# MMCSD_MMC_48300000h register map
Vendor: Texas Instruments
Registers are 32-bit, access per field, reset values left out (the file's numbers can be read two ways) unless marked. A register's access mark holds for its fields unless they carry their own. Offsets are as the file gives them; [hi:lo] are bit positions.

## MMC (part 3 of 3)
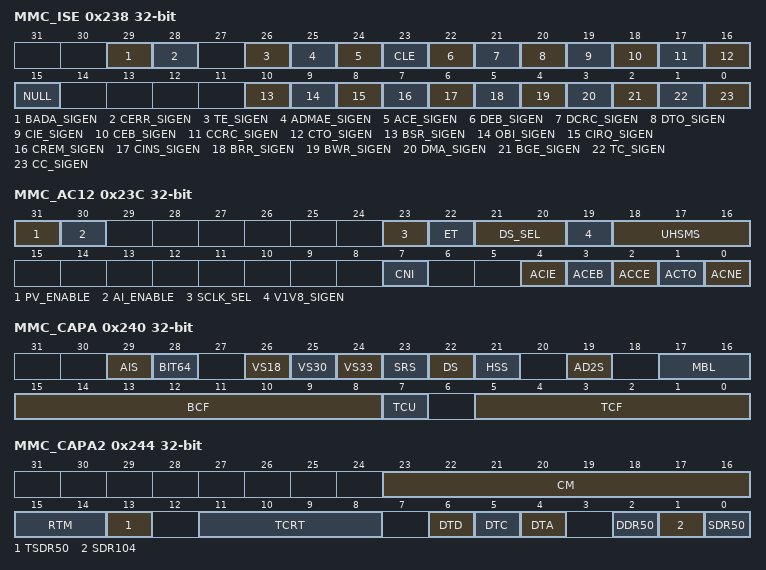
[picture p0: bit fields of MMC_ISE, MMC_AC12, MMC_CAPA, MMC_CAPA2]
0x238 MMC_ISE — Interrupt Signal Enable Register This register allows to enable/disable the module internal sources of status, on an event-by-event basis. MMCHS_ISE[31:16] = Error Interrupt Signal Enable MMCHS_ISE[15:0] = Normal Interrupt Signal Enable.
  [29] BADA_SIGEN rw — Bad access to data space Signal Enable 0 Masked1 Enabled
  [28] CERR_SIGEN rw — Card Error Interrupt Signal Enable 0 Masked1 Enabled
  [26] TE_SIGEN rw — Tuning Error Signal Enable 0 Masked1 Enabled
  [25] ADMAE_SIGEN rw — ADMA Error Signal Enable 0 Masked1 Enabled
  [24] ACE_SIGEN rw — Auto CMD Error Signal Enable 0 Masked1 Enabled
  [23] CLE ro — Reserved bit.Current limit error is not supported.These bits are initialized to zero, and writes to them are ignored.
  [22] DEB_SIGEN rw — Data End Bit Error Signal Enable 0 Masked1 Enabled
  [21] DCRC_SIGEN rw — Data CRC Error Signal Enable 0 Masked1 Enabled
  [20] DTO_SIGEN rw — Data Timeout Error Signal Enable 0 Masked1 Enabled
  [19] CIE_SIGEN rw — Command Index Error Signal Enable 0 Masked1 Enabled
  [18] CEB_SIGEN rw — Command End Bit Error Signal Enable 0 Masked1 Enabled
  [17] CCRC_SIGEN rw — Command CRC Error Signal Enable 0 Masked1 Enabled
  [16] CTO_SIGEN rw — Command timeout Error Signal Enable 0 Masked1 Enabled
  [15] NULL ro — Fixed to 0The host driver shall control error interrupts using the Error Interrupt Signal Enable register.Writes to this bit are ignored
  [10] BSR_SIGEN rw — Boot Status Signal Enable A write to this register when MMCSD_CON[BOOT_ACK] is set to 0x0 is ignored. 0 Masked1 Enabled
  [9] OBI_SIGEN rw — Out-Of-Band Interrupt Signal Enable A write to this register when MMCSD_CON[OBIE] is set to '0' is ignored. 0 Masked1 Enabled
  [8] CIRQ_SIGEN rw — Card Interrupt Signal Enable 0 Masked1 Enabled
  [7] CREM_SIGEN rw — Card Removal Signal Enable 0 Masked1 Enabled
  [6] CINS_SIGEN rw — Card Insertion Signal Enable 0 Masked1 Enabled
  [5] BRR_SIGEN rw — Buffer Read Ready Signal Enable 0 Masked1 Enabled
  [4] BWR_SIGEN rw — Buffer Write Ready Signal Enable 0 Masked1 Enabled
  [3] DMA_SIGEN rw — DMA Interrupt Signal Enable 0 Masked1 Enabled
  [2] BGE_SIGEN rw — Black Gap Event Signal Enable 0 Masked1 Enabled
  [1] TC_SIGEN rw — Transfer Completed Status Enable 0 Masked1 Enabled
  [0] CC_SIGEN rw — Command Complete Status Enable 0 Masked1 Enabled
0x23C MMC_AC12 — Host Control 2 Register and Auto CMD Error Status Register This register is used to indicate CMD12 response error of Auto CMD12 and CMD23 response error of Auto CMD23. The Host driver can determine what kind of Auto CMD12 / CMD23 errors occur by this register. Auto CMD23 errors are indicated in bit 04-01.This register is valid only when the Auto CMD Error is set.
  [31] PV_ENABLE rw — Preset Value Enable Host Controller Version 3.00 supports this bit. As the operating SDCLK frequency and I/O driver strength depend on the Host System implementation, it is difficult to determine these parameters in the Standard Host Driver. When Preset Value Enable is set, automatic SDCLK frequency generation and driver strength selection is performed without considering system specific conditions. This bit enables the functions defined in the Preset Value registers. If this bit is set to 0, SDCLK Frequency Select, Clock Generator Select in the Clock Control register and Driver Strength Select in Host Control 2 register are set by Host Driver. If this bit is set to 1, SDCLK Frequency Select, Clock Generator Select in the Clock Control register and Driver Strength Select in Host Control 2 register are set by Host Controller as specified in the Preset Value registers. 0 SDCLK and Driver Strength are controlled by Host Driver.1 Automatic Selection by Preset Value are Enabled.
  [30] AI_ENABLE rw — Asynchronous Interrupt Enable This bit can be set to 1 if a card supports asynchronous interrupts and Asynchronous Interrupt Support is set to 1 in the Capabilities register. Asynchronous interrupt is effective when DAT[1] interrupt is used in 4-bit SD mode [and zero is set to Interrupt Pin Select in the Shared Bus Control register]. If this bit is set to 1, the Host Driver can stop the SDCLK during asynchronous interrupt period to save power. During this period, the Host Controller continues to deliver the Card Interrupt to the host when it is asserted by the Card. 0 Disabled1 Enabled
  [23] SCLK_SEL rw — Sampling Clock Select Host Controller uses this bit to select sampling clock to receive CMD and DAT. This bit is set by tuning procedure and valid after the completion of tuning [when Execute Tuning is cleared]. Setting 1 means that tuning is completed successfully and setting 0 means that tuning is failed. Writing 1 to this bit is meaningless and ignored. A tuning circuit is reset by Writing to 0. This bit can be cleared with setting Execute Tuning. Once the tuning circuit is reset, it will take time to complete tuning sequence. Therefore, Host Driver should keep this bit to 1 to perform re-tuning sequence to compete re-tuning sequence in a short time. Change of this bit is not allowed while the Host Controller is receiving response or a read data block. 0 Fixed clock is used to sample data1 Tuned clock is used to sample data
  [22] ET rw — Execute Tuning This bit is set to 1 to start tuning procedure and automatically cleared when tuning procedure is completed. The result of tuning is indicated to Sampling Clock Select. Tuning procedure is aborted by Writing 0. This is Read-Write with automatic clear register 0 Not Tuned or Tuning Completed1 Execute Tuning
  [21:20] DS_SEL rw — Driver Strength Select Host Controller output driver in 1.8V signaling is selected by this bit. In 3.3V signaling, this field is not effective. This field can be set depends on Driver Type A, C and D support bits in the Capabilities register. This bit depends on setting of Preset Value Enable. If Preset Value Enable = 0, this field is set by Host Driver. If Preset Value Enable = 1, this field is automatically set by a value specified in the one of Preset Value registers. 0 Driver Type B is selected (Default)1 Driver Type A is selected2 Driver Type C is selected3 Driver Type D is selected
  [19] V1V8_SIGEN rw — 1.8V Signaling Enable This bit controls voltage regulator for I/O cell. 3.3V is supplied to the card regardless of signaling voltage. Setting this bit from 0 to 1 starts changing signal voltage from 3.3V to 1.8V. 1.8V regulator output shall be stable within 5ms. Host Controller clears this bit if switching to 1.8V signaling fails. Clearing this bit from 1 to 0 starts changing signal voltage from 1.8V to 3.3V. 3.3V regulator output shall be stable within 5ms. Host Driver can set this bit to 1 when Host Controller supports 1.8V signaling [One of support bits is set to1:SDR50, SDR104 or DDR50 in the Capabilities register] and the card or device supports UHS-I [S18A=1. Refer to Bus Signal Voltage Switch Sequence in the Physical Layer Specification Version 3.0x]. 0 3.3V Signaling1 1.8V Signaling
  [18:16] UHSMS rw — UHS Mode Select This field is used to select one of UHS-I modes and effective when 1.8V Signaling Enable is set to 1. If Preset Value Enable in the Host Control 2 register is set to 1, Host Controller sets SDCLK Frequency Select, Clock Generator Select in the Clock Control register and Driver Strength Select according to Preset Value registers. In this case, one of preset value registers is selected by this field. Host Driver needs to reset SD Clock Enable before changing this field to avoid generating clock glitch. After setting this field, Host Driver sets SD Clock Enable again. When SDR50, SDR104 or DDR50 is selected for SDIO card, interrupt detection at the block gap shall not be used. Read Wait timing is changed for these modes. Refer to the SDIO Specification Version 3.00 for more detail. 0 SDR121 SDR252 SDR503 SDR1044 DDR505 Reserved6 Reserved7 Reserved
  [7] CNI ro — Command Not Issued By Auto CMD12 Error Setting this bit to 1 means CMD_wo_DAT is not executed due to an Auto CMD12 Error [D04-D01] in this register. This bit is set to 0 when Auto CMD Error is generated by Auto CMD23. 0 Not error1 Command not issued
  [4] ACIE ro — Auto CMD Index Error This bit is set if the Command Index error occurs in response to a command. 0 No error1 Error
  [3] ACEB ro — Auto CMD End Bit Error This bit is set when detecting that the end bit of command response is 0. 0 No error1 End bit Error Generated
  [2] ACCE ro — Auto CMD CRC Error This bit is set when detecting a CRC error in the command response. 0 No error1 CRC Error Generated
  [1] ACTO ro — Auto CMD Timeout Error This bit is set if no response is returned within 64 SDCLK cycles from the end bit of command. If this bit is set to1, the other error status bits [D04-D02] are meaningless. 0 No error1 Auto CMD Time Out
  [0] ACNE ro — Auto CMD12 Not Executed If memory multiple block data transfer is not started due to command error, this bit is not set because it is not necessary to issue Auto CMD12. Setting this bit to 1 means the Host Controller cannot issue Auto CMD12 to stop memory multiple block data transfer due to some error. If this bit is set to 1, other error status bits [D04-D01] are meaningless. This bit is set to 0 when Auto CMD Error is generated by Auto CMD23. 0 Auto CMD12 Executed1 Auto CMD12 Not Executed
0x240 MMC_CAPA — Capabilities Register This register lists the capabilities of the MMC/SD/SDIO host controller.
  [29] AIS ro — Asynchronous Interrupt Support Refer to SDIO Specification Version 3.00 about asynchronous interrupt. 0 Asynchronous Interrupt Not Supported1 Asynchronous Interrupt Supported
  [28] BIT64 ro — 64 Bit System Bus Support Setting 1 to this bit indicates that the Host Controller supports 64-bit address descriptor mode and is connected to 64-bit address system bus. 0 32 bit System bus address1 64 bit System bus address
  [26] VS18 rw — Voltage support 1.8V Initialization of this register [via a write access to this register] depends on the system capabilities. The host driver shall not modify this register after the initilaization. This register is only reinitialized by a hard reset [via RESETN signal] 0 1.8V Not supported0 1.8V Not Supported1 1.8V Supported1 1.8V Supported
  [25] VS30 rw — Voltage support 3.0V Initialization of this register [via a write access to this register] depends on the system capabilities. The host driver shall not modify this register after the initilaization. This register is only reinitialized by a hard reset [via RESETN signal] 0 3.0V Not supported0 3.0V Not Supported1 3.0V Supported1 3.0V Supported
  [24] VS33 rw — Voltage support 3.3V Initialization of this register [via a write access to this register] depends on the system capabilities. The host driver shall not modify this register after the initilaization. This register is only reinitialized by a hard reset [via RESETN signal] 0 3.3V Not supported0 3.3V Not Supported1 3.3V Supported1 3.3V Supported
  [23] SRS ro — Suspend/Resume support [SDIO cards only] This bit indicates whether the host controller supports Suspend/Resume functionality. 0 The Host controller does not Suspend/Resume functionality.1 The Host controller supports Suspend/Resume functionality.
  [22] DS ro — DMA supportThis bit indicates that the Host Controller is able to use DMA to transfer data between system memory and the Host Controller directly. 0 DMA Not Supported1 DMA Supported
  [21] HSS ro — High speed support This bit indicates that the host controller supports high speed operations and can supply an up-to maximum card frequency. 0 High Speed Not Supported1 High Speed Supported
  [19] AD2S ro — ADMA2 Support This bit indicates whether the Host Controller is capable of using ADMA2. It depends on setting of generic parameter MADMA_EN 0 ADMA2 not Supported1 ADMA2 Supported
  [17:16] MBL ro — Maximum block lengthThis value indicates the maximum block size that the host driver can read and write to the buffer in the host controller.This value depends on definition of generic parameter with a max value of2048bytes.The host controller supports 512 bytes and1024bytes block transfers. 0 512 bytes1 1024 bytes2 2048 bytes
  [15:8] BCF ro — Base Clock Frequency For SD Clock This value indicates the base [maximum] clock frequency for the SD Clock. 8-bit Base Clock Frequency This mode is supported by the Host Controller Version 3.00. Unit values are 1MHz. The supported clock range is 10MHz to 255MHz. FFh : 255MHz .... : ....... 02h: 2MHz 01h: 1MHz 00h: Get information via another method If the real frequency is 16.5MHz, the lager value shall be set00010001b[17MHz] because the Host Driver use this value to calculate the clock divider value [Refer to the SDCLK Frequency Select in the Clock Control register.] and it shall not exceed upper limit of the SD Clock frequency. If these bits are all 0, the Host System has to get information via another method. 0 The value indicating the base (maximum) frequency for the output clock provided to the card is system dependent and is not available in this register. Get the information via another method.
  [7] TCU ro — Timeout clock unitThis bit shows the unit of base clock frequency used to detect Data Timeout Error [MMCSD_STAT[DTO]]. 0 KHz1 MHz
  [5:0] TCF ro — Timeout clock frequencyThe timeout clock frequency is used to detect Data Timeout Error [MMCSD_STAT[DTO]]. 0 The timeout clock frequency depends on the frequency of the clock provided to the card. The value of the timeout clock frequency is not available in this register.
0x244 MMC_CAPA2 ro — Capabilities 2 Register This register provides the Host Driver with information specific to the Host Controller implementation. The Host Controller may implement these values as fixed or loaded from flash memory during power on initialization. Refer to Software Reset For All in the Software Reset register for loading from flash memory and completion timing control.
  [23:16] CM — Clock Multiplier This field indicates clock multiplier value of programmable clock generator. Refer to Clock Control register. Setting00hmeans that Host Controller does not support programmable clock generator. 00h: Clock Multiplier is Not Supported 01h: Clock Multiplier M = 2 02h: Clock Multiplier M = 3 .... : ...................... FFh : Clock Multiplier M = 256
  [15:14] RTM — Re-Tuning Modes This field selects re-tuning method and limits the maximum data length. Bit47-46 Re-Tuning Mode Re-Tuning Method Data Length There are two re-tuning timings: Re-Tuning Request controlled by the Host Controller and expiration of a Re-Tuning Timer controlled by the Host Driver. By receiving either timing, the Host Driver executes the re-tuning procedure just before a next command issue. The maximum data length per read/write command is restricted so that re-tuning procedures can be inserted during data transfers. [1] Re-Tuning Mode 1 The host controller does not have any internal logic to detect when the re-tuning needs to be performed. In this case, the Host Driver should maintain all re-tuning timings by using a Re-Tuning Timer. To enable inserting the re-tuning procedure during data transfers, the data length per read/write command shall be limited up to 4MB. [2] Re-Tuning Mode 2 The host controller has the capability to indicate the re-tuning timing by Re-Tuning Request during data transfers. Then the data length per read/write command shall be limited up to 4MB. During non data transfer, re-tuning timing is determined by either Re-Tuning Request or Re-Tuning Timer. If Re-Tuning Request is used, Re-Tuning Timer should be disabled. [3] Re-Tuning Mode 3 The host controller has the capability to take care of the re-tuning during data transfer [Auto Re-Tuning]. Re-Tuning Request shall not be generated during data transfers and there is no limitation to data length per read/write command. During non data transfer, re-tuning timing is determined by either Re-Tuning Request or Re-Tuning Timer. If Re-Tuning Request is used, Re-Tuning Timer should be disabled. Re-Tuning Timer Control Example for Re-Tuning Mode 1 The initial value of re-tuning timer is provided by Timer Count for Re-Tuning field in this register. The timer starts counting by loading the initial value. When the timer expires, the Host Driver marks an expiration flag. On receiving a command request, the Host driver checks the expiration flag. If the expiration flag is set, then the Host Driver should perform the re-tuning procedure before issuing a command. If the expiration flag is not set, then the Host Driver issues a command without performing the re-tuning procedure. Every time the re-tuning procedure is performed, the timer loads the new initial value and the expiration flag is cleared. Re-Tuning Timer Control Example for Re-Tuning Mode 2 and Mode 3 The timer control is almost the same as Re-Tuning Mode 1 except the timer loads the new initial value after data transfer [when receiving Transfer Complete]. In case of Mode 3, Timer Count for Re-Tuning is set either smaller value: Tuning effective time after re-tuning procedure or after data transfer. If a Host System goes into power down mode, the Host Driver should stop the re-tuning timer and set the expiration flag to 1 when the Host System resumes from power down mode. 0 Timer - Max data length 4MB1 Timer and Re-Tuning Request - Max data length 4MB2 Auto Re-Tuning (for transfer) - Timer and Re-Tuning Request3 Reserved
  [13] TSDR50 — Use Tuning for SDR50 If this bit is set to 1, this Host Controller requires tuning to operate SDR50. [Tuning is always required to operate SDR104.] 0 SDR50 does not require tuning.1 SDR50 requires tuning.
  [11:8] TCRT — Timer Count for Re-Tuning This field indicates an initial value of the Re-Tuning Timer for Re-Tuning Mode 1 to 3. Setting to 0 disables Re-Tuning Timer. 0 Re-Tuning Timer disabled1 1 second2 2 seconds3 4 seconds4 8 seconds5 16 seconds6 32 seconds7 64 seconds8 128 seconds9 256 seconds10 512 seconds11 1024 seconds12 Reserved13 Reserved14 Reserved15 Get information from other source
  [6] DTD — Driver Type D Support This bit indicates support of Driver Type D for 1.8 Signaling. 0 Driver Type D is Not Supported.1 Driver Type D is Supported
  [5] DTC — Driver Type C Support This bit indicates support of Driver Type C for 1.8 Signaling. 0 Driver Type C is Not Supported.1 Driver Type C is Supported.
  [4] DTA — Driver Type A Support This bit indicates support of Driver Type A for 1.8 Signaling. 0 Driver Type A is Not Supported.1 Driver Type A is Supported.
  [2] DDR50 — DDR50 Support 0 DDR50 is Not Supported.1 DDR50 is Supported.
  [1] SDR104 — SDR104 Support SDR104 requires tuning. 0 SDR104 is Not Supported.1 SDR104 is Supported.
  [0] SDR50 — SDR50 Support If SDR104 is supported, this bit shall be set to 1. Bit 13 indicates whether SDR50 requires tuning or not. 0 SDR50 is Not Supported.1 SDR50 is Supported.
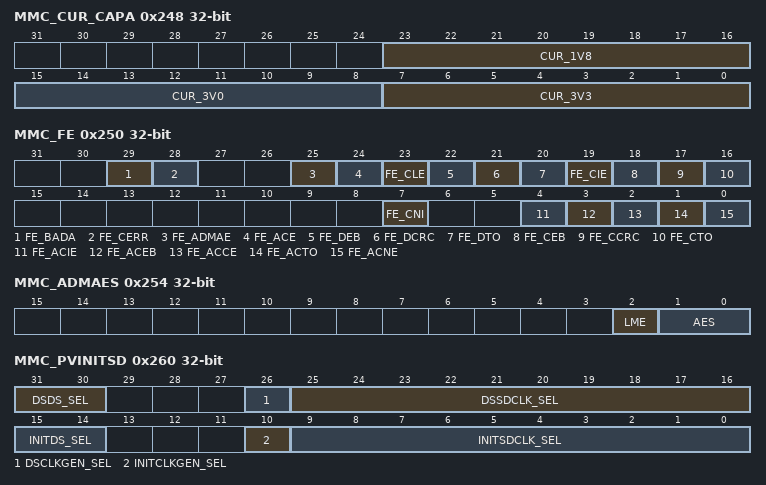
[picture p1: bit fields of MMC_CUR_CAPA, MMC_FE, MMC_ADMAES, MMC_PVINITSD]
0x248 MMC_CUR_CAPA — Maximum Current Capabilities Register This register indicates the maximum current capability for each voltage. The value is meaningful if the voltage support is set in the capabilities register (MMCHS_CAPA). Initialization of this register (via a write access to this register) depends on the system capabilities. The host driver shall not modify this register after the initilaization. This register is only reinitialized by a hard reset (via RESETN signal).
  [23:16] CUR_1V8 rw — Maximum current for 1.8V 0 The maximum current capability for this voltage is not available. Feature not implemented.
  [15:8] CUR_3V0 rw — Maximum current for 3.0V 0 The maximum current capability for this voltage is not available. Feature not implemented.
  [7:0] CUR_3V3 rw — Maximum current for 3.3V 0 The maximum current capability for this voltage is not available. Feature not implemented.
0x250 MMC_FE access not given — Force Event Register for Auto CMD Error Status and Error Interrupt status The Force Event Register is not a physically implemented register. Rather, it is an address at which the Auto CMD Error Status Register can be written. Writing 1 : set each bit of the Auto CMD Error Status Register Writing 0 : no effect Rather, it is an address at which the Error Interrupt Status register can be written. The effect of a write to this address will be reflected in the Error Interrupt Status Register if the corresponding bit of the Error Interrupt Status Enable Register is set. Writing 1 : set each bit of the Error Interrupt Status Register Writing 0 : no effect Note: By setting this register, the Error Interrupt can be set in the Error Interrupt Status register. In order to generate interrupt signal, both the Error Interrupt Status Enable and Error Interrupt Signal Enable shall be set.
  [29] FE_BADA wo — Force Event Bad access to data space. 0 No effect, No Interrupt.1 Interrupt Forced
  [28] FE_CERR wo — Force Event Card error. 0 No effect, No Interrupt.1 Interrupt Forced
  [25] FE_ADMAE wo — Force Event ADMA Error. 0 No effect, No Interrupt.1 Interrupt Forced
  [24] FE_ACE wo — Force Event for Auto CMD Error 0 No effect, No Interrupt.1 Interrupt Forced
  [23] FE_CLE — Reserved. Current limit error is not supported. These bits are initialized to zero, and writes to them are ignored.
  [22] FE_DEB wo — Force Event Data End Bit error. 0 No effect, No Interrupt.1 Interrupt Forced
  [21] FE_DCRC wo — Force Event Data CRC Error. 0 No effect, No Interrupt.1 Interrupt Forced
  [20] FE_DTO wo — Force Event Data Timeout Error. 0 No effect, No Interrupt.1 Interrupt Forced
  [19] FE_CIE wo — Force Event Command Index Error. 0 No effect, No Interrupt.1 Interrupt Forced
  [18] FE_CEB wo — Force Event Command End Bit Error. 0 No effect, No Interrupt.1 Interrupt Forced
  [17] FE_CCRC wo — Force Event Command CRC Error. 0 No effect, No Interrupt.1 Interrupt Forced
  [16] FE_CTO wo — Command Timeout ErrorThis bit is set automatically when no response is received within 64 clock cycles from the end bit of the command.For commands that reply within 5 clock cycles - the timeout is still detected at 64 clock cycles. 0 Status bit unchanged1 Status is cleared
  [7] FE_CNI wo — Force Event Command not issue by Auto CMD12 error 0 No effect, No Interrupt.1 Interrupt Forced
  [4] FE_ACIE wo — Force Event for Auto CMD Index Error 0 No effect, No Interrupt.1 Interrupt Forced
  [3] FE_ACEB wo — Force Event Auto CMD End Bit Error 0 No effect, No Interrupt.1 Interrupt Forced
  [2] FE_ACCE wo — Force Event Auto CMD CRC Error 0 No effect, No Interrupt.1 Interrupt Forced
  [1] FE_ACTO wo — Force Event Auto CMD Timeout Error 0 No effect, No Interrupt.1 Interrupt Forced
  [0] FE_ACNE wo — Force Event Auto CMD12 Not Executed 0 No effect, No Interrupt.1 Interrupt Forced
0x254 MMC_ADMAES — ADMA Error Status Register When ADMA Error Interrupt is occurred, the ADMA Error States field in this register holds the ADMA state and the ADMA System Address Register holds the address around the error descriptor. For recovering the error, the Host Driver requires the ADMA state to identify the error descriptor address as follows: ST_STOP: Previous location set in the ADMA System Address register is the error descriptor address ST_FDS: Current location set in the ADMA System Address register is the error descriptor address ST_CADR: This sate is never set because do not generate ADMA error in this state. ST_TFR: Previous location set in the ADMA System Address register is the error descriptor address In case of write operation, the Host Driver should use ACMD22 to get the number of written block rather than using this information, since unwritten data may exist in the Host Controller. The Host Controller generates the ADMA Error Interrupt when it detects invalid descriptor data (Valid=0) at the ST_FDS state. In this case, ADMA Error State indicates that an error occurs at ST_FDS state. The Host Driver may find that the Valid bit is not set in the error descriptor.
  [2] LME rw — ADMA Length Mismatch Error:[1] While Block Count Enable being set, the total data length specified by the Descriptor table is different from that specified by the Block Count and Block Length.[2] Total data length can not be divided by the block length. 0 No Error1 Error
  [1:0] AES rw — ADMA Error State his field indicates the state of ADMA when error is occurred during ADMA data transfer. This field never indicates '10' because ADMA never stops in this state. 0 ST_STOP (Stop DMA)Contents of SYS_SDR register1 ST_STOP (Stop DMA)Points the error descriptor2 Never set this state(Not used)3 ST_TFR (Transfer Data)Points the next of the error descriptor
0x258 MMC_ADMASAL rw — ADMA System address Low bits.
  [31:0] ADMA_A32B — ADMA System address 32 bits.This register holds byte address of executing command of the Descriptor table. 32-bit Address Descriptor uses lower 32-bit of this register. At the start of ADMA, the Host Driver shall set start address of the Descriptor table. The ADMA increments this register address, which points to next line, when every fetching a Descriptor line. When the ADMA Error Interrupt is generated, this register shall hold valid Descriptor address depending on the ADMA state. The Host Driver shall program Descriptor Table on 32-bit boundary and set 32-bit boundary address to this register. ADMA2 ignores lower 2-bit of this register and assumes it to be00b
0x260 MMC_PVINITSD ro — Preset Value for Initialization and Default Speed modes.
  [31:30] DSDS_SEL — Driver Strength Select Value - Default Speed mode Driver Strength is supported by 1.8V signaling bus speed modes. This field is meaningless for 3.3V signaling. 0 Driver Type B is Selected.1 Driver Type A is Selected.2 Driver Type C is Selected.3 Driver Type D is Selected.
  [26] DSCLKGEN_SEL — Clock Generator Select Value - Default Speed mode This bit is effective when Host Controller supports programmable clock generator. 0 Host Controller Ver2.00 Compatible Clock Generator.1 Programmable Clock Generator.
  [25:16] DSSDCLK_SEL — SDCLK Frequency Select Value - Default Speed mode 10-bit preset value to set SDCLK Frequency Select in the Clock Control Register is described by a host system.
  [15:14] INITDS_SEL — Driver Strength Select Value - Initialization mode Driver Strength is supported by 1.8V signaling bus speed modes. This field is meaningless for 3.3V signaling. 0 Driver Type B is Selected1 Driver Type A is Selected2 Driver Type C is Selected3 Driver Type D is Selected
  [10] INITCLKGEN_SEL — Clock Generator Select Value - Initialization mode This bit is effective when Host Controller supports programmable clock generator. 0 Host Controller Ver2.00 Compatible Clock Generator.1 Programmable Clock Generator.
  [9:0] INITSDCLK_SEL — SDCLK Frequency Select Value - Initialization mode 10-bit preset value to set SDCLK Frequency Select in the Clock Control Register is described by a host system.
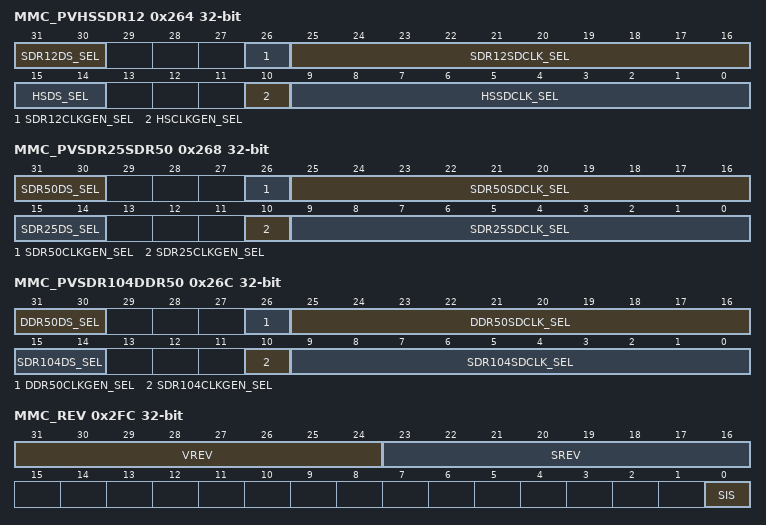
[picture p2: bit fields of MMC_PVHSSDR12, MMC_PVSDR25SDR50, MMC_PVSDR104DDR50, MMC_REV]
0x264 MMC_PVHSSDR12 ro — Preset Value for High Speed and SDR12 speed modes.
  [31:30] SDR12DS_SEL — Driver Strength Select Value - SDR12 mode Driver Strength is supported by 1.8V signaling bus speed modes. This field is meaningless for 3.3V signaling. 0 Driver Type B is Selected.1 Driver Type A is Selected.2 Driver Type C is Selected.3 Driver Type D is Selected.
  [26] SDR12CLKGEN_SEL — Clock Generator Select Value - SDR12 mode This bit is effective when Host Controller supports programmable clock generator. 0 Host Controller Ver2.00 Compatible Clock Generato.1 Programmable Clock Generator.
  [25:16] SDR12SDCLK_SEL — SDCLK Frequency Select Value - SDR12 mode 10-bit preset value to set SDCLK Frequency Select in the Clock Control Register is described by a host system.
  [15:14] HSDS_SEL — Driver Strength Select Value - High Speed mode Driver Strength is supported by 1.8V signaling bus speed modes. This field is meaningless for 3.3V signaling. 0 Driver Type B is Selected.1 Driver Type A is Selected.2 Driver Type C is Selected.3 Driver Type D is Selected.
  [10] HSCLKGEN_SEL — Clock Generator Select Value - High Speed mode This bit is effective when Host Controller supports programmable clock generator. 0 Host Controller Ver2.00 Compatible Clock Generator.1 Programmable Clock Generator.
  [9:0] HSSDCLK_SEL — SDCLK Frequency Select Value - High Speed mode 10-bit preset value to set SDCLK Frequency Select in the Clock Control Register is described by a host system.
0x268 MMC_PVSDR25SDR50 ro — Preset Value for SDR25 and SDR50 speed modes.
  [31:30] SDR50DS_SEL — Driver Strength Select Value - SDR50 mode Driver Strength is supported by 1.8V signaling bus speed modes. This field is meaningless for 3.3V signaling. 0 Driver Type B is Selected.1 Driver Type A is Selected.2 Driver Type C is Selected.3 Driver Type D is Selected.
  [26] SDR50CLKGEN_SEL — Clock Generator Select Value - SDR50 mode This bit is effective when Host Controller supports programmable clock generator. 0 Host Controller Ver2.00 Compatible Clock Generator.1 Programmable Clock Generator.
  [25:16] SDR50SDCLK_SEL — SDCLK Frequency Select Value - SDR50 mode 10-bit preset value to set SDCLK Frequency Select in the Clock Control Register is described by a host system.
  [15:14] SDR25DS_SEL — Driver Strength Select Value - SDR25 mode Driver Strength is supported by 1.8V signaling bus speed modes. This field is meaningless for 3.3V signaling. 0 Driver Type B is Selected.1 Driver Type A is Selected.2 Driver Type C is Selected.3 Driver Type D is Selected.
  [10] SDR25CLKGEN_SEL — Clock Generator Select Value - SDR25 mode This bit is effective when Host Controller supports programmable clock generator. 0 Host Controller Ver2.00 Compatible Clock Generator.1 Programmable Clock Generato.
  [9:0] SDR25SDCLK_SEL — SDCLK Frequency Select Value - SDR25 mode 10-bit preset value to set SDCLK Frequency Select in the Clock Control Register is described by a host system.
0x26C MMC_PVSDR104DDR50 ro — Preset Value for SDR104 and DDR50 speed modes.
  [31:30] DDR50DS_SEL — Driver Strength Select Value - DDR50 mode Driver Strength is supported by 1.8V signaling bus speed modes. This field is meaningless for 3.3V signaling. 0 Driver Type B is Selected.1 Driver Type A is Selected.2 Driver Type C is Selected.3 Driver Type D is Selected.
  [26] DDR50CLKGEN_SEL — Clock Generator Select Value - DDR50 mode This bit is effective when Host Controller supports programmable clock generator. 0 Host Controller Ver2.00 Compatible Clock Generator1 Programmable Clock Generator
  [25:16] DDR50SDCLK_SEL — SDCLK Frequency Select Value - DDR50 mode 10-bit preset value to set SDCLK Frequency Select in the Clock Control Register is described by a host system.
  [15:14] SDR104DS_SEL — Driver Strength Select Value - SDR104 mode Driver Strength is supported by 1.8V signaling bus speed modes. This field is meaningless for 3.3V signaling. 0 Driver Type B is Selected.1 Driver Type A is Selected.2 Driver Type C is Selected.3 Driver Type D is Selected.
  [10] SDR104CLKGEN_SEL — Clock Generator Select Value - SDR104 mode This bit is effective when Host Controller supports programmable clock generator. 0 Host Controller Ver2.00 Compatible Clock Generator.1 Programmable Clock Generator.
  [9:0] SDR104SDCLK_SEL — SDCLK Frequency Select Value - SDR104 mode 10-bit preset value to set SDCLK Frequency Select in the Clock Control Register is described by a host system.
0x2FC MMC_REV ro — Versions RegisterThis register contains the hard coded RTL vendor revision number, the version number of SD specification compliancy and a slot status bit.MMCHS_REV[31:16] = Host controller versionMMCHS_REV[15:0] = Slot Interrupt Status.
  [31:24] VREV — Vendor Version Number: IP revision[7:4] Major revision[3:0] Minor revisionExamples: 0x10 for 1.0 0x21 for 2.1
  [23:16] SREV — Specification Version Number This status indicates the Host Controller Spec. Version. The upper and lower 4-bits indicate the version. 0 SD Host Specification Version 1.00.1 SD Host Specification Version 2.00 - Including the feature of the ADMA and Test Register.2 SD Host Specification Version 3.00.3 Reserved
  [0] SIS — Slot Interrupt StatusThis status bit indicates the inverted state of interrupt signal for the module.By a power on reset or by setting a software reset for all [MMCSD_HCTL[SRA]], the interrupt signal shall be de-asserted and this status shall read 0.
